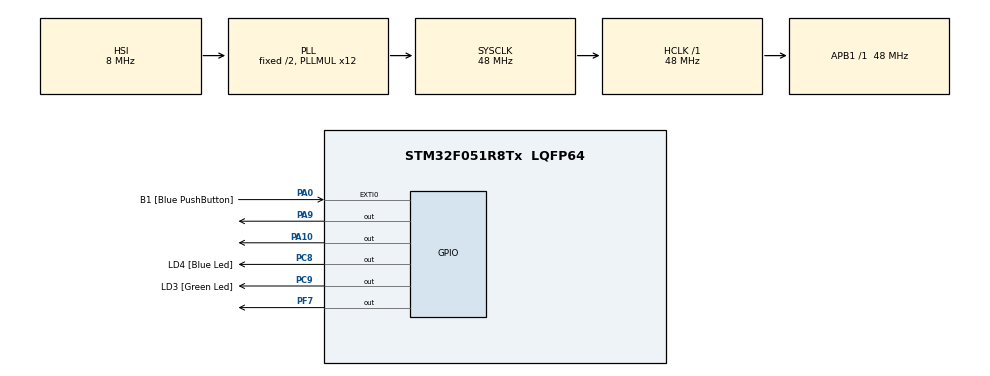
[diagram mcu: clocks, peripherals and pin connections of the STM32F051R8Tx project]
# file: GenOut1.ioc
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Mcu.Family=STM32F0
Mcu.Name=STM32F051R8Tx
Mcu.Package=LQFP64
PA0.GPIO_Label=B1 [Blue PushButton]
PA0.GPIO_ModeDefaultEXTI=GPIO_MODE_EVT_RISING
PA0.Signal=GPXTI0
PA10.Signal=GPIO_Output
PA13.GPIO_Label=SWDIO
PA13.Signal=SYS_SWDIO
PA14.GPIO_Label=SWCLK
PA14.Signal=SYS_SWCLK
PA9.Signal=GPIO_Output
PC8.GPIO_Label=LD4 [Blue Led]
PC8.Signal=GPIO_Output
PC9.GPIO_Label=LD3 [Green Led]
PC9.Signal=GPIO_Output
PF7.Signal=GPIO_Output
ProjectManager.HeapSize=0x200
ProjectManager.StackSize=0x400
ProjectManager.TargetToolchain=MDK-ARM V5
RCC.AHBFreq_Value=48000000
RCC.APB1Freq_Value=48000000
RCC.APB1TimFreq_Value=48000000
RCC.HCLKFreq_Value=48000000
RCC.PLLMUL=RCC_PLL_MUL12
RCC.SYSCLKFreq_VALUE=48000000
RCC.SYSCLKSource=RCC_SYSCLKSOURCE_PLLCLK
board=STM32F0DISCOVERY

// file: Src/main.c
/**
  ******************************************************************************
  * File Name          : main.c
  * Description        : Main program body
  ******************************************************************************
  *
  * COPYRIGHT(c) 2016 STMicroelectronics
  *
  * Redistribution and use in source and binary forms, with or without modification,
  * are permitted provided that the following conditions are met:
  *   1. Redistributions of source code must retain the above copyright notice,
  *      this list of conditions and the following disclaimer.
  *   2. Redistributions in binary form must reproduce the above copyright notice,
  *      this list of conditions and the following disclaimer in the documentation
  *      and/or other materials provided with the distribution.
  *   3. Neither the name of STMicroelectronics nor the names of its contributors
  *      may be used to endorse or promote products derived from this software
  *      without specific prior written permission.
  *
  * THIS SOFTWARE IS PROVIDED BY THE COPYRIGHT HOLDERS AND CONTRIBUTORS "AS IS"
  * AND ANY EXPRESS OR IMPLIED WARRANTIES, INCLUDING, BUT NOT LIMITED TO, THE
  * IMPLIED WARRANTIES OF MERCHANTABILITY AND FITNESS FOR A PARTICULAR PURPOSE ARE
  * DISCLAIMED. IN NO EVENT SHALL THE COPYRIGHT HOLDER OR CONTRIBUTORS BE LIABLE
  * FOR ANY DIRECT, INDIRECT, INCIDENTAL, SPECIAL, EXEMPLARY, OR CONSEQUENTIAL
  * DAMAGES (INCLUDING, BUT NOT LIMITED TO, PROCUREMENT OF SUBSTITUTE GOODS OR
  * SERVICES; LOSS OF USE, DATA, OR PROFITS; OR BUSINESS INTERRUPTION) HOWEVER
  * CAUSED AND ON ANY THEORY OF LIABILITY, WHETHER IN CONTRACT, STRICT LIABILITY,
  * OR TORT (INCLUDING NEGLIGENCE OR OTHERWISE) ARISING IN ANY WAY OUT OF THE USE
  * OF THIS SOFTWARE, EVEN IF ADVISED OF THE POSSIBILITY OF SUCH DAMAGE.
  *
  ******************************************************************************
  */
#include "main.h"
#include "stm32f0xx_hal.h"

/* USER CODE BEGIN PV */
/* Private variables ---------------------------------------------------------*/

/* USER CODE END PV */

void SystemClock_Config(void);
void Error_Handler(void);
static void MX_GPIO_Init(void);

/* USER CODE BEGIN PFP */
/* Private function prototypes -----------------------------------------------*/

/* USER CODE END PFP */

int main(void)
{

  /* MCU Configuration----------------------------------------------------------*/

  /* Reset of all peripherals, Initializes the Flash interface and the Systick. */
  HAL_Init();

  /* Configure the system clock */
  SystemClock_Config();

  /* Initialize all configured peripherals */
  MX_GPIO_Init();

  /* Infinite loop */
  while (1)
  {

  /* USER CODE BEGIN 3 */
			HAL_GPIO_TogglePin(GPIOA,GPIO_PIN_9) ;	   // Toggling this pin should create the interrupt
      HAL_GPIO_TogglePin(GPIOC,LD4_Pin) ;			   // Toggle the LED state
	    HAL_Delay(1000) ;
  }
  /* USER CODE END 3 */

}

/** System Clock Configuration
*/
void SystemClock_Config(void)
{

  RCC_OscInitTypeDef RCC_OscInitStruct;
  RCC_ClkInitTypeDef RCC_ClkInitStruct;

    /**Initializes the CPU, AHB and APB busses clocks
    */
  RCC_OscInitStruct.OscillatorType = RCC_OSCILLATORTYPE_HSI;
  RCC_OscInitStruct.HSIState = RCC_HSI_ON;
  RCC_OscInitStruct.HSICalibrationValue = 16;
  RCC_OscInitStruct.PLL.PLLState = RCC_PLL_ON;
  RCC_OscInitStruct.PLL.PLLSource = RCC_PLLSOURCE_HSI;
  RCC_OscInitStruct.PLL.PLLMUL = RCC_PLL_MUL12;
  RCC_OscInitStruct.PLL.PREDIV = RCC_PREDIV_DIV1;
  if (HAL_RCC_OscConfig(&RCC_OscInitStruct) != HAL_OK)
  {
    Error_Handler();
  }

    /**Initializes the CPU, AHB and APB busses clocks
    */
  RCC_ClkInitStruct.ClockType = RCC_CLOCKTYPE_HCLK|RCC_CLOCKTYPE_SYSCLK
                              |RCC_CLOCKTYPE_PCLK1;
  RCC_ClkInitStruct.SYSCLKSource = RCC_SYSCLKSOURCE_PLLCLK;
  RCC_ClkInitStruct.AHBCLKDivider = RCC_SYSCLK_DIV1;
  RCC_ClkInitStruct.APB1CLKDivider = RCC_HCLK_DIV1;

  if (HAL_RCC_ClockConfig(&RCC_ClkInitStruct, FLASH_LATENCY_1) != HAL_OK)
  {
    Error_Handler();
  }

    /**Configure the Systick interrupt time
    */
  HAL_SYSTICK_Config(HAL_RCC_GetHCLKFreq()/1000);

    /**Configure the Systick
    */
  HAL_SYSTICK_CLKSourceConfig(SYSTICK_CLKSOURCE_HCLK);

  /* SysTick_IRQn interrupt configuration */
  HAL_NVIC_SetPriority(SysTick_IRQn, 0, 0);
}

/** Configure pins as
        * Analog
        * Input
        * Output
        * EVENT_OUT
        * EXTI
*/
static void MX_GPIO_Init(void)
{

  GPIO_InitTypeDef GPIO_InitStruct;

  /* GPIO Ports Clock Enable */
  __HAL_RCC_GPIOA_CLK_ENABLE();
  __HAL_RCC_GPIOC_CLK_ENABLE();
  __HAL_RCC_GPIOF_CLK_ENABLE();

  /*Configure GPIO pin : B1_Pin */
  GPIO_InitStruct.Pin = B1_Pin;
  GPIO_InitStruct.Mode = GPIO_MODE_IT_RISING;
  GPIO_InitStruct.Pull = GPIO_NOPULL;
  HAL_GPIO_Init(B1_GPIO_Port, &GPIO_InitStruct);

	/* Enable and set EXTI line 0 Interrupt to the lowest priority */
  HAL_NVIC_SetPriority(EXTI0_1_IRQn, 2, 0);
  HAL_NVIC_EnableIRQ(EXTI0_1_IRQn);

  /*Configure GPIO pins : LD4_Pin LD3_Pin */
  GPIO_InitStruct.Pin = LD4_Pin|LD3_Pin;
  GPIO_InitStruct.Mode = GPIO_MODE_OUTPUT_PP;
  GPIO_InitStruct.Pull = GPIO_NOPULL;
  GPIO_InitStruct.Speed = GPIO_SPEED_FREQ_LOW;
  HAL_GPIO_Init(GPIOC, &GPIO_InitStruct);

  /*Configure GPIO pins : PA9 PA10 */
  GPIO_InitStruct.Pin = GPIO_PIN_9|GPIO_PIN_10;
  GPIO_InitStruct.Mode = GPIO_MODE_OUTPUT_PP;
  GPIO_InitStruct.Pull = GPIO_NOPULL;
  GPIO_InitStruct.Speed = GPIO_SPEED_FREQ_LOW;
  HAL_GPIO_Init(GPIOA, &GPIO_InitStruct);

  /*Configure GPIO pin : PF7 */
  GPIO_InitStruct.Pin = GPIO_PIN_7;
  GPIO_InitStruct.Mode = GPIO_MODE_OUTPUT_PP;
  GPIO_InitStruct.Pull = GPIO_NOPULL;
  GPIO_InitStruct.Speed = GPIO_SPEED_FREQ_LOW;
  HAL_GPIO_Init(GPIOF, &GPIO_InitStruct);

  /*Configure GPIO pin Output Level */
  HAL_GPIO_WritePin(GPIOC, LD4_Pin|LD3_Pin, GPIO_PIN_RESET);

  /*Configure GPIO pin Output Level */
  HAL_GPIO_WritePin(GPIOA, GPIO_PIN_9|GPIO_PIN_10, GPIO_PIN_RESET);

  /*Configure GPIO pin Output Level */
  HAL_GPIO_WritePin(GPIOF, GPIO_PIN_7, GPIO_PIN_RESET);

}

void Error_Handler(void)
{
  while(1)
  {
  }
}

void EXTI0_1_IRQHandler(uint16_t GPIO_Pin)
{
  /* EXTI line interrupt detected */
	EXTI->PR |= EXTI_PR_PR0 ;             // Clear the interrupt
	HAL_GPIO_TogglePin(GPIOC,LD3_Pin) ;		// Toggle the LED
}

/************************ (C) COPYRIGHT STMicroelectronics *****END OF FILE****/
